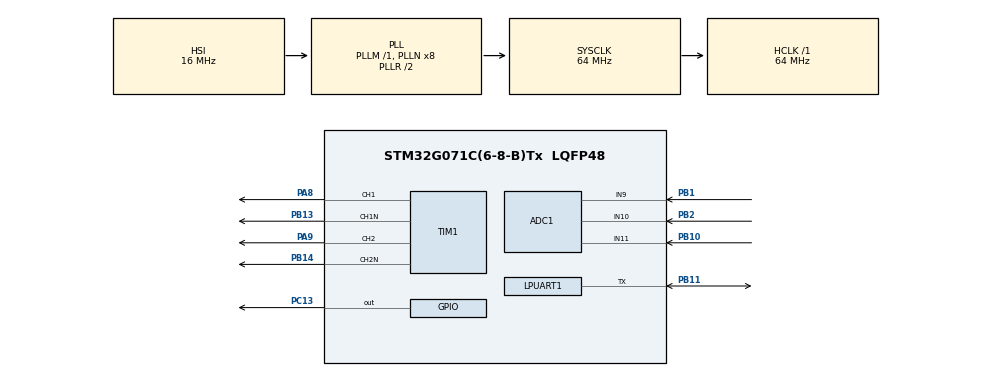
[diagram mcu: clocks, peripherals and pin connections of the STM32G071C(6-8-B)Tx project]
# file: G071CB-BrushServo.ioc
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ADC1.Channel-3\#ChannelRegularConversion=ADC_CHANNEL_VREFINT
ADC1.Channel-4\#ChannelRegularConversion=ADC_CHANNEL_9
ADC1.Channel-5\#ChannelRegularConversion=ADC_CHANNEL_10
ADC1.Channel-6\#ChannelRegularConversion=ADC_CHANNEL_11
ADC1.Channel-7\#ChannelRegularConversion=ADC_CHANNEL_TEMPSENSOR
ADC1.ClockPrescaler=ADC_CLOCK_SYNC_PCLK_DIV2
ADC1.EOCSelection=ADC_EOC_SEQ_CONV
ADC1.NbrOfConversion=5
ADC1.NbrOfConversionFlag=1
ADC1.OversamplingMode=DISABLE
ADC1.Rank-3\#ChannelRegularConversion=1
ADC1.Rank-4\#ChannelRegularConversion=2
ADC1.Rank-5\#ChannelRegularConversion=3
ADC1.Rank-6\#ChannelRegularConversion=4
ADC1.Rank-7\#ChannelRegularConversion=5
ADC1.SamplingTime-3\#ChannelRegularConversion=ADC_SAMPLINGTIME_COMMON_1
ADC1.SamplingTime-4\#ChannelRegularConversion=ADC_SAMPLINGTIME_COMMON_1
ADC1.SamplingTime-5\#ChannelRegularConversion=ADC_SAMPLINGTIME_COMMON_1
ADC1.SamplingTime-6\#ChannelRegularConversion=ADC_SAMPLINGTIME_COMMON_1
ADC1.SamplingTime-7\#ChannelRegularConversion=ADC_SAMPLINGTIME_COMMON_1
ADC1.SamplingTimeCommon1=ADC_SAMPLETIME_160CYCLES_5
ADC1.SamplingTimeCommon2=ADC_SAMPLETIME_1CYCLE_5
ADC1.SelectedChannel=ADC_CHANNEL_TEMPSENSOR|ADC_CHANNEL_VREFINT|ADC_CHANNEL_9|ADC_CHANNEL_10|ADC_CHANNEL_11
ADC1.TriggerFrequencyMode=ADC_TRIGGER_FREQ_LOW
ADC1.master=1
Dma.ADC1.0.Direction=DMA_PERIPH_TO_MEMORY
Dma.ADC1.0.EventEnable=DISABLE
Dma.ADC1.0.Instance=DMA1_Channel1
Dma.ADC1.0.MemDataAlignment=DMA_MDATAALIGN_HALFWORD
Dma.ADC1.0.MemInc=DMA_MINC_ENABLE
Dma.ADC1.0.Mode=DMA_NORMAL
Dma.ADC1.0.PeriphDataAlignment=DMA_PDATAALIGN_HALFWORD
Dma.ADC1.0.PeriphInc=DMA_PINC_DISABLE
Dma.ADC1.0.Polarity=HAL_DMAMUX_REQ_GEN_RISING
Dma.ADC1.0.Priority=DMA_PRIORITY_LOW
Dma.ADC1.0.RequestNumber=1
Dma.ADC1.0.SignalID=NONE
Dma.ADC1.0.SyncEnable=DISABLE
Dma.ADC1.0.SyncPolarity=HAL_DMAMUX_SYNC_NO_EVENT
Dma.ADC1.0.SyncRequestNumber=1
Dma.ADC1.0.SyncSignalID=NONE
Dma.LPUART1_RX.2.Direction=DMA_PERIPH_TO_MEMORY
Dma.LPUART1_RX.2.EventEnable=DISABLE
Dma.LPUART1_RX.2.Instance=DMA1_Channel3
Dma.LPUART1_RX.2.MemDataAlignment=DMA_MDATAALIGN_BYTE
Dma.LPUART1_RX.2.MemInc=DMA_MINC_ENABLE
Dma.LPUART1_RX.2.Mode=DMA_NORMAL
Dma.LPUART1_RX.2.PeriphDataAlignment=DMA_PDATAALIGN_BYTE
Dma.LPUART1_RX.2.PeriphInc=DMA_PINC_DISABLE
Dma.LPUART1_RX.2.Polarity=HAL_DMAMUX_REQ_GEN_RISING
Dma.LPUART1_RX.2.Priority=DMA_PRIORITY_LOW
Dma.LPUART1_RX.2.RequestNumber=1
Dma.LPUART1_RX.2.SignalID=NONE
Dma.LPUART1_RX.2.SyncEnable=DISABLE
Dma.LPUART1_RX.2.SyncPolarity=HAL_DMAMUX_SYNC_NO_EVENT
Dma.LPUART1_RX.2.SyncRequestNumber=1
Dma.LPUART1_RX.2.SyncSignalID=NONE
Dma.LPUART1_TX.1.Direction=DMA_MEMORY_TO_PERIPH
Dma.LPUART1_TX.1.EventEnable=DISABLE
Dma.LPUART1_TX.1.Instance=DMA1_Channel2
Dma.LPUART1_TX.1.MemDataAlignment=DMA_MDATAALIGN_BYTE
Dma.LPUART1_TX.1.MemInc=DMA_MINC_ENABLE
Dma.LPUART1_TX.1.Mode=DMA_NORMAL
Dma.LPUART1_TX.1.PeriphDataAlignment=DMA_PDATAALIGN_BYTE
Dma.LPUART1_TX.1.PeriphInc=DMA_PINC_DISABLE
Dma.LPUART1_TX.1.Polarity=HAL_DMAMUX_REQ_GEN_RISING
Dma.LPUART1_TX.1.Priority=DMA_PRIORITY_LOW
Dma.LPUART1_TX.1.RequestNumber=1
Dma.LPUART1_TX.1.SignalID=NONE
Dma.LPUART1_TX.1.SyncEnable=DISABLE
Dma.LPUART1_TX.1.SyncPolarity=HAL_DMAMUX_SYNC_NO_EVENT
Dma.LPUART1_TX.1.SyncRequestNumber=1
Dma.LPUART1_TX.1.SyncSignalID=NONE
Dma.Request0=ADC1
Dma.Request1=LPUART1_TX
Dma.Request2=LPUART1_RX
LPUART1.BaudRate=921600
LPUART1.DMADisableonRxErrorParam=UART_ADVFEATURE_DMA_DISABLEONRXERROR
LPUART1.FifoMode=UART_FIFOMODE_DISABLE
LPUART1.OverrunDisableParam=UART_ADVFEATURE_OVERRUN_DISABLE
LPUART1.WordLength=UART_WORDLENGTH_8B
Mcu.Family=STM32G0
Mcu.Name=STM32G071C(6-8-B)Tx
Mcu.Package=LQFP48
NVIC.DMA1_Channel1_IRQn=true\:0\:0\:false\:false\:true\:false\:true\:true
NVIC.DMA1_Channel2_3_IRQn=true\:0\:0\:false\:false\:true\:false\:true\:true
NVIC.TIM6_DAC_LPTIM1_IRQn=true\:2\:0\:true\:false\:true\:true\:true\:true
NVIC.TIM7_LPTIM2_IRQn=true\:3\:0\:false\:false\:true\:false\:true\:true
NVIC.TimeBase=TIM7_LPTIM2_IRQn
NVIC.TimeBaseIP=TIM7
NVIC.USART3_4_LPUART1_IRQn=true\:2\:0\:true\:false\:true\:true\:true\:true
PA13.Mode=Serial_Wire
PA13.Signal=SYS_SWDIO
PA14-BOOT0.Mode=Serial_Wire
PA14-BOOT0.Signal=SYS_SWCLK
PA8.Signal=S_TIM1_CH1
PA9.Signal=S_TIM1_CH2
PB1.Mode=IN9
PB1.Signal=ADC1_IN9
PB10.Mode=IN11
PB10.Signal=ADC1_IN11
PB11.GPIO_Speed=GPIO_SPEED_FREQ_VERY_HIGH
PB11.Mode=Half_duplex(single_wire_mode)
PB11.PinState=GPIO_PIN_SET
PB11.Signal=LPUART1_TX
PB13.Mode=PWM Generation1 CH1 CH1N
PB13.Signal=TIM1_CH1N
PB14.Mode=PWM Generation2 CH2 CH2N
PB14.Signal=TIM1_CH2N
PB2.Mode=IN10
PB2.Signal=ADC1_IN10
PC13.Signal=GPIO_Output
ProjectManager.HeapSize=0x200
ProjectManager.StackSize=0x400
ProjectManager.TargetToolchain=STM32CubeIDE
RCC.ADCFreq_Value=64000000
RCC.AHBFreq_Value=64000000
RCC.CortexFreq_Value=64000000
RCC.EXTERNAL_CLOCK_VALUE=48000
RCC.HCLKFreq_Value=64000000
RCC.HSE_VALUE=8000000
RCC.HSI_VALUE=16000000
RCC.LSE_VALUE=32768
RCC.SYSCLKFreq_VALUE=64000000
RCC.SYSCLKSource=RCC_SYSCLKSOURCE_PLLCLK
RCC.VCOOutputFreq_Value=128000000
SH.S_TIM1_CH1.0=TIM1_CH1,PWM Generation1 CH1 CH1N
SH.S_TIM1_CH2.0=TIM1_CH2,PWM Generation2 CH2 CH2N
TIM1.AutoReloadPreload=TIM_AUTORELOAD_PRELOAD_ENABLE
TIM1.Channel-PWM\ Generation1\ CH1\ CH1N=TIM_CHANNEL_1
TIM1.Channel-PWM\ Generation2\ CH2\ CH2N=TIM_CHANNEL_2
TIM1.OC2Preload_PWM=ENABLE
TIM1.OCFastMode_PWM-PWM\ Generation1\ CH1\ CH1N=TIM_OCFAST_DISABLE
TIM1.OCFastMode_PWM-PWM\ Generation2\ CH2\ CH2N=TIM_OCFAST_DISABLE
TIM1.OCPolarity_1=TIM_OCPOLARITY_LOW
TIM1.OCPolarity_2=TIM_OCPOLARITY_LOW
TIM6.Period=999
TIM6.Prescaler=63
VP_ADC1_TempSens_Input.Mode=IN-TempSens
VP_ADC1_Vref_Input.Mode=IN-Vrefint
VP_SYS_VS_tim7.Mode=TIM7
VP_TIM1_VS_ClockSourceINT.Mode=Internal
VP_TIM2_VS_ClockSourceINT.Mode=Internal
VP_TIM6_VS_ClockSourceINT.Mode=Enable_Timer
board=custom

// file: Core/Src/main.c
/* USER CODE BEGIN Header */
/**
  ******************************************************************************
  * @file           : main.c
  * @brief          : Main program body
  ******************************************************************************
  * @attention
  *
  * Copyright (c) 2023 STMicroelectronics.
  * All rights reserved.
  *
  * This software is licensed under terms that can be found in the LICENSE file
  * in the root directory of this software component.
  * If no LICENSE file comes with this software, it is provided AS-IS.
  *
  ******************************************************************************
  */
/* USER CODE END Header */
#include "main.h"

/* USER CODE BEGIN Includes */
#include "Components/start.h"
/* USER CODE END Includes */

ADC_HandleTypeDef hadc1;
DMA_HandleTypeDef hdma_adc1;

UART_HandleTypeDef hlpuart1;
DMA_HandleTypeDef hdma_lpuart1_tx;
DMA_HandleTypeDef hdma_lpuart1_rx;

TIM_HandleTypeDef htim1;
TIM_HandleTypeDef htim2;
TIM_HandleTypeDef htim6;

void SystemClock_Config(void);
static void MX_GPIO_Init(void);
static void MX_DMA_Init(void);
static void MX_ADC1_Init(void);
static void MX_LPUART1_UART_Init(void);
static void MX_TIM1_Init(void);
static void MX_TIM6_Init(void);
static void MX_TIM2_Init(void);

int main(void)
{

  /* MCU Configuration--------------------------------------------------------*/

  /* Reset of all peripherals, Initializes the Flash interface and the Systick. */
  HAL_Init();

  /* Configure the system clock */
  SystemClock_Config();

  /* Initialize all configured peripherals */
  MX_GPIO_Init();
  MX_DMA_Init();
  MX_ADC1_Init();
  MX_LPUART1_UART_Init();
  MX_TIM1_Init();
  MX_TIM6_Init();
  MX_TIM2_Init();
  /* USER CODE BEGIN 2 */
  HAL_TIM_Base_Start(&htim2);
  start();
  /* USER CODE END 2 */

  /* Infinite loop */
  while (1)
  {

  }
}

void SystemClock_Config(void)
{
  RCC_OscInitTypeDef RCC_OscInitStruct = {0};
  RCC_ClkInitTypeDef RCC_ClkInitStruct = {0};

  /** Configure the main internal regulator output voltage
  */
  HAL_PWREx_ControlVoltageScaling(PWR_REGULATOR_VOLTAGE_SCALE1);

  /** Initializes the RCC Oscillators according to the specified parameters
  * in the RCC_OscInitTypeDef structure.
  */
  RCC_OscInitStruct.OscillatorType = RCC_OSCILLATORTYPE_HSI;
  RCC_OscInitStruct.HSIState = RCC_HSI_ON;
  RCC_OscInitStruct.HSIDiv = RCC_HSI_DIV1;
  RCC_OscInitStruct.HSICalibrationValue = RCC_HSICALIBRATION_DEFAULT;
  RCC_OscInitStruct.PLL.PLLState = RCC_PLL_ON;
  RCC_OscInitStruct.PLL.PLLSource = RCC_PLLSOURCE_HSI;
  RCC_OscInitStruct.PLL.PLLM = RCC_PLLM_DIV1;
  RCC_OscInitStruct.PLL.PLLN = 8;
  RCC_OscInitStruct.PLL.PLLP = RCC_PLLP_DIV2;
  RCC_OscInitStruct.PLL.PLLQ = RCC_PLLQ_DIV2;
  RCC_OscInitStruct.PLL.PLLR = RCC_PLLR_DIV2;
  if (HAL_RCC_OscConfig(&RCC_OscInitStruct) != HAL_OK)
  {
    Error_Handler();
  }

  /** Initializes the CPU, AHB and APB buses clocks
  */
  RCC_ClkInitStruct.ClockType = RCC_CLOCKTYPE_HCLK|RCC_CLOCKTYPE_SYSCLK
                              |RCC_CLOCKTYPE_PCLK1;
  RCC_ClkInitStruct.SYSCLKSource = RCC_SYSCLKSOURCE_PLLCLK;
  RCC_ClkInitStruct.AHBCLKDivider = RCC_SYSCLK_DIV1;
  RCC_ClkInitStruct.APB1CLKDivider = RCC_HCLK_DIV1;

  if (HAL_RCC_ClockConfig(&RCC_ClkInitStruct, FLASH_LATENCY_2) != HAL_OK)
  {
    Error_Handler();
  }
}

static void MX_ADC1_Init(void)
{

  ADC_ChannelConfTypeDef sConfig = {0};

  /** Configure the global features of the ADC (Clock, Resolution, Data Alignment and number of conversion)
  */
  hadc1.Instance = ADC1;
  hadc1.Init.ClockPrescaler = ADC_CLOCK_SYNC_PCLK_DIV2;
  hadc1.Init.Resolution = ADC_RESOLUTION_12B;
  hadc1.Init.DataAlign = ADC_DATAALIGN_RIGHT;
  hadc1.Init.ScanConvMode = ADC_SCAN_ENABLE;
  hadc1.Init.EOCSelection = ADC_EOC_SEQ_CONV;
  hadc1.Init.LowPowerAutoWait = DISABLE;
  hadc1.Init.LowPowerAutoPowerOff = DISABLE;
  hadc1.Init.ContinuousConvMode = DISABLE;
  hadc1.Init.NbrOfConversion = 5;
  hadc1.Init.DiscontinuousConvMode = DISABLE;
  hadc1.Init.ExternalTrigConv = ADC_SOFTWARE_START;
  hadc1.Init.ExternalTrigConvEdge = ADC_EXTERNALTRIGCONVEDGE_NONE;
  hadc1.Init.DMAContinuousRequests = DISABLE;
  hadc1.Init.Overrun = ADC_OVR_DATA_PRESERVED;
  hadc1.Init.SamplingTimeCommon1 = ADC_SAMPLETIME_160CYCLES_5;
  hadc1.Init.SamplingTimeCommon2 = ADC_SAMPLETIME_1CYCLE_5;
  hadc1.Init.OversamplingMode = DISABLE;
  hadc1.Init.TriggerFrequencyMode = ADC_TRIGGER_FREQ_LOW;
  if (HAL_ADC_Init(&hadc1) != HAL_OK)
  {
    Error_Handler();
  }

  /** Configure Regular Channel
  */
  sConfig.Channel = ADC_CHANNEL_VREFINT;
  sConfig.Rank = ADC_REGULAR_RANK_1;
  sConfig.SamplingTime = ADC_SAMPLINGTIME_COMMON_1;
  if (HAL_ADC_ConfigChannel(&hadc1, &sConfig) != HAL_OK)
  {
    Error_Handler();
  }

  /** Configure Regular Channel
  */
  sConfig.Channel = ADC_CHANNEL_9;
  sConfig.Rank = ADC_REGULAR_RANK_2;
  if (HAL_ADC_ConfigChannel(&hadc1, &sConfig) != HAL_OK)
  {
    Error_Handler();
  }

  /** Configure Regular Channel
  */
  sConfig.Channel = ADC_CHANNEL_10;
  sConfig.Rank = ADC_REGULAR_RANK_3;
  if (HAL_ADC_ConfigChannel(&hadc1, &sConfig) != HAL_OK)
  {
    Error_Handler();
  }

  /** Configure Regular Channel
  */
  sConfig.Channel = ADC_CHANNEL_11;
  sConfig.Rank = ADC_REGULAR_RANK_4;
  if (HAL_ADC_ConfigChannel(&hadc1, &sConfig) != HAL_OK)
  {
    Error_Handler();
  }

  /** Configure Regular Channel
  */
  sConfig.Channel = ADC_CHANNEL_TEMPSENSOR;
  sConfig.Rank = ADC_REGULAR_RANK_5;
  if (HAL_ADC_ConfigChannel(&hadc1, &sConfig) != HAL_OK)
  {
    Error_Handler();
  }

}

static void MX_LPUART1_UART_Init(void)
{

  hlpuart1.Instance = LPUART1;
  hlpuart1.Init.BaudRate = 921600;
  hlpuart1.Init.WordLength = UART_WORDLENGTH_8B;
  hlpuart1.Init.StopBits = UART_STOPBITS_1;
  hlpuart1.Init.Parity = UART_PARITY_NONE;
  hlpuart1.Init.Mode = UART_MODE_TX_RX;
  hlpuart1.Init.HwFlowCtl = UART_HWCONTROL_NONE;
  hlpuart1.Init.OneBitSampling = UART_ONE_BIT_SAMPLE_DISABLE;
  hlpuart1.Init.ClockPrescaler = UART_PRESCALER_DIV1;
  hlpuart1.AdvancedInit.AdvFeatureInit = UART_ADVFEATURE_RXOVERRUNDISABLE_INIT|UART_ADVFEATURE_DMADISABLEONERROR_INIT;
  hlpuart1.AdvancedInit.OverrunDisable = UART_ADVFEATURE_OVERRUN_DISABLE;
  hlpuart1.AdvancedInit.DMADisableonRxError = UART_ADVFEATURE_DMA_DISABLEONRXERROR;
  hlpuart1.FifoMode = UART_FIFOMODE_DISABLE;
  if (HAL_HalfDuplex_Init(&hlpuart1) != HAL_OK)
  {
    Error_Handler();
  }
  if (HAL_UARTEx_SetTxFifoThreshold(&hlpuart1, UART_TXFIFO_THRESHOLD_1_8) != HAL_OK)
  {
    Error_Handler();
  }
  if (HAL_UARTEx_SetRxFifoThreshold(&hlpuart1, UART_RXFIFO_THRESHOLD_1_8) != HAL_OK)
  {
    Error_Handler();
  }
  if (HAL_UARTEx_DisableFifoMode(&hlpuart1) != HAL_OK)
  {
    Error_Handler();
  }

}

static void MX_TIM1_Init(void)
{

  TIM_ClockConfigTypeDef sClockSourceConfig = {0};
  TIM_MasterConfigTypeDef sMasterConfig = {0};
  TIM_OC_InitTypeDef sConfigOC = {0};
  TIM_BreakDeadTimeConfigTypeDef sBreakDeadTimeConfig = {0};

  htim1.Instance = TIM1;
  htim1.Init.Prescaler = 0;
  htim1.Init.CounterMode = TIM_COUNTERMODE_UP;
  htim1.Init.Period = 65535;
  htim1.Init.ClockDivision = TIM_CLOCKDIVISION_DIV1;
  htim1.Init.RepetitionCounter = 0;
  htim1.Init.AutoReloadPreload = TIM_AUTORELOAD_PRELOAD_ENABLE;
  if (HAL_TIM_Base_Init(&htim1) != HAL_OK)
  {
    Error_Handler();
  }
  sClockSourceConfig.ClockSource = TIM_CLOCKSOURCE_INTERNAL;
  if (HAL_TIM_ConfigClockSource(&htim1, &sClockSourceConfig) != HAL_OK)
  {
    Error_Handler();
  }
  if (HAL_TIM_PWM_Init(&htim1) != HAL_OK)
  {
    Error_Handler();
  }
  sMasterConfig.MasterOutputTrigger = TIM_TRGO_RESET;
  sMasterConfig.MasterOutputTrigger2 = TIM_TRGO2_RESET;
  sMasterConfig.MasterSlaveMode = TIM_MASTERSLAVEMODE_DISABLE;
  if (HAL_TIMEx_MasterConfigSynchronization(&htim1, &sMasterConfig) != HAL_OK)
  {
    Error_Handler();
  }
  sConfigOC.OCMode = TIM_OCMODE_PWM1;
  sConfigOC.Pulse = 0;
  sConfigOC.OCPolarity = TIM_OCPOLARITY_LOW;
  sConfigOC.OCNPolarity = TIM_OCNPOLARITY_HIGH;
  sConfigOC.OCFastMode = TIM_OCFAST_DISABLE;
  sConfigOC.OCIdleState = TIM_OCIDLESTATE_RESET;
  sConfigOC.OCNIdleState = TIM_OCNIDLESTATE_RESET;
  if (HAL_TIM_PWM_ConfigChannel(&htim1, &sConfigOC, TIM_CHANNEL_1) != HAL_OK)
  {
    Error_Handler();
  }
  if (HAL_TIM_PWM_ConfigChannel(&htim1, &sConfigOC, TIM_CHANNEL_2) != HAL_OK)
  {
    Error_Handler();
  }
  sBreakDeadTimeConfig.OffStateRunMode = TIM_OSSR_DISABLE;
  sBreakDeadTimeConfig.OffStateIDLEMode = TIM_OSSI_DISABLE;
  sBreakDeadTimeConfig.LockLevel = TIM_LOCKLEVEL_OFF;
  sBreakDeadTimeConfig.DeadTime = 0;
  sBreakDeadTimeConfig.BreakState = TIM_BREAK_DISABLE;
  sBreakDeadTimeConfig.BreakPolarity = TIM_BREAKPOLARITY_HIGH;
  sBreakDeadTimeConfig.BreakFilter = 0;
  sBreakDeadTimeConfig.BreakAFMode = TIM_BREAK_AFMODE_INPUT;
  sBreakDeadTimeConfig.Break2State = TIM_BREAK2_DISABLE;
  sBreakDeadTimeConfig.Break2Polarity = TIM_BREAK2POLARITY_HIGH;
  sBreakDeadTimeConfig.Break2Filter = 0;
  sBreakDeadTimeConfig.Break2AFMode = TIM_BREAK_AFMODE_INPUT;
  sBreakDeadTimeConfig.AutomaticOutput = TIM_AUTOMATICOUTPUT_DISABLE;
  if (HAL_TIMEx_ConfigBreakDeadTime(&htim1, &sBreakDeadTimeConfig) != HAL_OK)
  {
    Error_Handler();
  }
  HAL_TIM_MspPostInit(&htim1);

}

static void MX_TIM2_Init(void)
{

  TIM_ClockConfigTypeDef sClockSourceConfig = {0};
  TIM_MasterConfigTypeDef sMasterConfig = {0};

  htim2.Instance = TIM2;
  htim2.Init.Prescaler = 0;
  htim2.Init.CounterMode = TIM_COUNTERMODE_UP;
  htim2.Init.Period = 4294967295;
  htim2.Init.ClockDivision = TIM_CLOCKDIVISION_DIV1;
  htim2.Init.AutoReloadPreload = TIM_AUTORELOAD_PRELOAD_DISABLE;
  if (HAL_TIM_Base_Init(&htim2) != HAL_OK)
  {
    Error_Handler();
  }
  sClockSourceConfig.ClockSource = TIM_CLOCKSOURCE_INTERNAL;
  if (HAL_TIM_ConfigClockSource(&htim2, &sClockSourceConfig) != HAL_OK)
  {
    Error_Handler();
  }
  sMasterConfig.MasterOutputTrigger = TIM_TRGO_RESET;
  sMasterConfig.MasterSlaveMode = TIM_MASTERSLAVEMODE_DISABLE;
  if (HAL_TIMEx_MasterConfigSynchronization(&htim2, &sMasterConfig) != HAL_OK)
  {
    Error_Handler();
  }

}

static void MX_TIM6_Init(void)
{

  TIM_MasterConfigTypeDef sMasterConfig = {0};

  htim6.Instance = TIM6;
  htim6.Init.Prescaler = 63;
  htim6.Init.CounterMode = TIM_COUNTERMODE_UP;
  htim6.Init.Period = 999;
  htim6.Init.AutoReloadPreload = TIM_AUTORELOAD_PRELOAD_DISABLE;
  if (HAL_TIM_Base_Init(&htim6) != HAL_OK)
  {
    Error_Handler();
  }
  sMasterConfig.MasterOutputTrigger = TIM_TRGO_RESET;
  sMasterConfig.MasterSlaveMode = TIM_MASTERSLAVEMODE_DISABLE;
  if (HAL_TIMEx_MasterConfigSynchronization(&htim6, &sMasterConfig) != HAL_OK)
  {
    Error_Handler();
  }

}

static void MX_DMA_Init(void)
{

  /* DMA controller clock enable */
  __HAL_RCC_DMA1_CLK_ENABLE();

  /* DMA interrupt init */
  /* DMA1_Channel1_IRQn interrupt configuration */
  HAL_NVIC_SetPriority(DMA1_Channel1_IRQn, 0, 0);
  HAL_NVIC_EnableIRQ(DMA1_Channel1_IRQn);
  /* DMA1_Channel2_3_IRQn interrupt configuration */
  HAL_NVIC_SetPriority(DMA1_Channel2_3_IRQn, 0, 0);
  HAL_NVIC_EnableIRQ(DMA1_Channel2_3_IRQn);

}

static void MX_GPIO_Init(void)
{
  GPIO_InitTypeDef GPIO_InitStruct = {0};

  /* GPIO Ports Clock Enable */
  __HAL_RCC_GPIOC_CLK_ENABLE();
  __HAL_RCC_GPIOB_CLK_ENABLE();
  __HAL_RCC_GPIOA_CLK_ENABLE();

  /*Configure GPIO pin Output Level */
  HAL_GPIO_WritePin(GPIOC, GPIO_PIN_13, GPIO_PIN_RESET);

  /*Configure GPIO pin : PC13 */
  GPIO_InitStruct.Pin = GPIO_PIN_13;
  GPIO_InitStruct.Mode = GPIO_MODE_OUTPUT_PP;
  GPIO_InitStruct.Pull = GPIO_NOPULL;
  GPIO_InitStruct.Speed = GPIO_SPEED_FREQ_LOW;
  HAL_GPIO_Init(GPIOC, &GPIO_InitStruct);

}

void HAL_TIM_PeriodElapsedCallback(TIM_HandleTypeDef *htim)
{
  if (htim->Instance == TIM7) {
    HAL_IncTick();
  }
}

void Error_Handler(void)
{
  __disable_irq();
  while (1)
  {
  }
}
